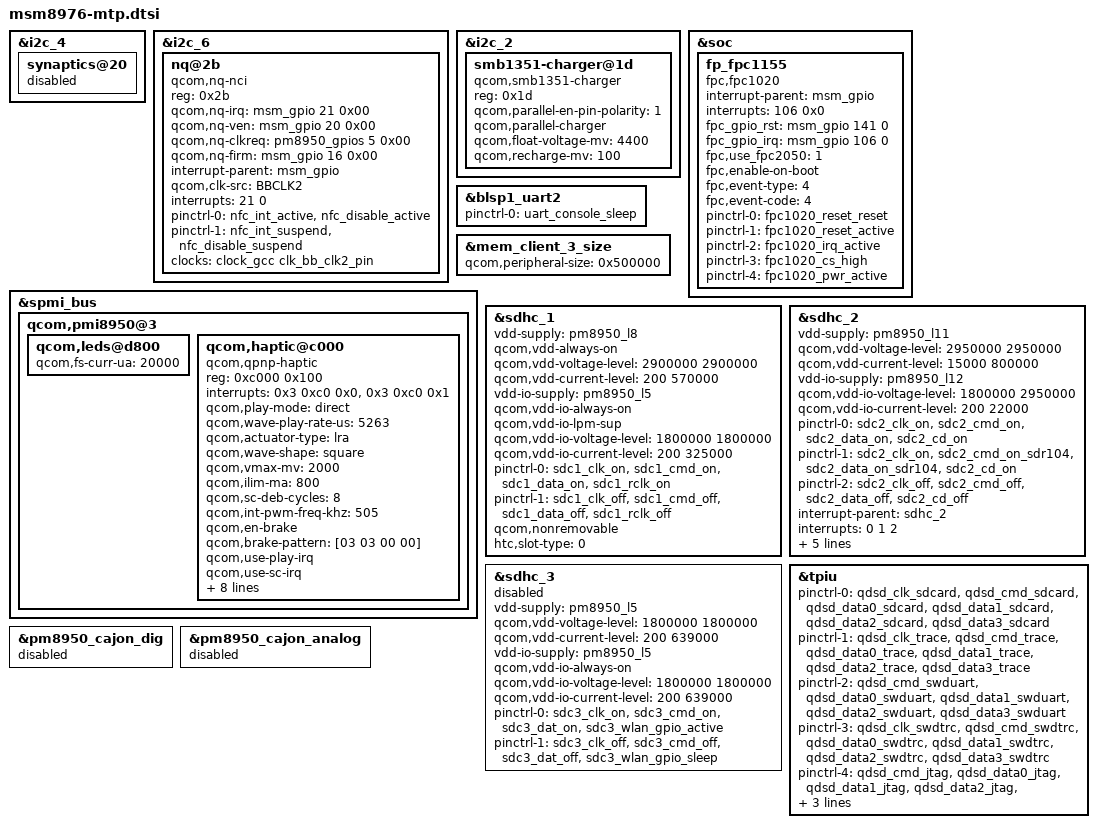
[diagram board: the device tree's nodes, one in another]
/*
 * Copyright (c) 2015, The Linux Foundation. All rights reserved.
 *
 * This program is free software; you can redistribute it and/or modify
 * it under the terms of the GNU General Public License version 2 and
 * only version 2 as published by the Free Software Foundation.
 *
 * This program is distributed in the hope that it will be useful,
 * but WITHOUT ANY WARRANTY; without even the implied warranty of
 * MERCHANTABILITY or FITNESS FOR A PARTICULAR PURPOSE.  See the
 * GNU General Public License for more details.
 */

#include "msm8976-pinctrl.dtsi"
/*#include "msm8976-mdss-mtp.dtsi"*/
#include "msm8976-wsa881x.dtsi"

&i2c_4 { /* BLSP1 QUP4 */
	synaptics@20 {
		status = "disable";
	};
};

&i2c_6 { /* BLSP2 QUP2 */
	nq@2b {
		compatible = "qcom,nq-nci";
		reg = <0x2b>;
		qcom,nq-irq = <&msm_gpio 21 0x00>;
		qcom,nq-ven = <&msm_gpio 20 0x00>;
		qcom,nq-clkreq = <&pm8950_gpios 5 0x00>;
		qcom,nq-firm = <&msm_gpio 16 0x00>;
		interrupt-parent = <&msm_gpio>;
		qcom,clk-src = "BBCLK2";
		interrupts = <21 0>;
		interrupt-names = "nfc_irq";
		pinctrl-names = "nfc_active", "nfc_suspend";
		pinctrl-0 = <&nfc_int_active &nfc_disable_active>;
		pinctrl-1 = <&nfc_int_suspend &nfc_disable_suspend>;
		clocks = <&clock_gcc clk_bb_clk2_pin>;
		clock-names = "ref_clk";
	};
};

&i2c_2 {
	/* Parallel-charger configuration */
	smb1351-charger@1d {
		compatible = "qcom,smb1351-charger";
		reg = <0x1d>;
		qcom,parallel-en-pin-polarity = <1>;
		qcom,parallel-charger;
		qcom,float-voltage-mv = <4400>;
		qcom,recharge-mv = <100>;
	};
};

// Fingerprint +++
&soc{
   fp_fpc1155 {
         compatible = "fpc,fpc1020";
                 interrupt-parent  = <&msm_gpio>;
                 interrupts        = <106 0x0>;
                 fpc_gpio_rst = <&msm_gpio 141 0>;
                 fpc_gpio_irq = <&msm_gpio 106 0>;
                 fpc,use_fpc2050   = <1>;
                 fpc,enable-on-boot;
                 /delete-property/ fpc,enable-wakeup;
                 // EV_MSC, MSC_SCAN
                 fpc,event-type = <4>;
                 fpc,event-code = <4>;
                 pinctrl-names     = "fpc1020_reset_reset",
                                     "fpc1020_reset_active",
                                     "fpc1020_irq_active",
                                     "fpc1020_cs_high",
                                     "fpc1020_pwr_active";
                                     //"fpc1020_spi_active",
                                     //"fpc1020_spi_suspend",
                 pinctrl-0         = <&fpc1020_reset_reset>;
                 pinctrl-1         = <&fpc1020_reset_active>;
                 pinctrl-2         = <&fpc1020_irq_active>;
                 pinctrl-3         = <&fpc1020_cs_high>;
                 pinctrl-4         = <&fpc1020_pwr_active>;
                 //pinctrl-3         = <&fpc1020_spi_active>;
                 //pinctrl-4         = <&fpc1020_spi_suspend>;

    };
};
// Fingerprint ---

//HTC_AUD++
/*
&soc {

	sound-9335 {
		qcom,msm-gpios =
			"quin_i2s",
			"us_eu_gpio";
		qcom,pinctrl-names =
			"all_off",
			"quin_act",
			"us_eu_gpio_act",
			"quin_us_eu_gpio_act";
		pinctrl-names =
			"all_off",
			"quin_act",
			"us_eu_gpio_act",
			"quin_us_eu_gpio_act";
		pinctrl-0 = <&pri_tlmm_lines_sus &cross_conn_det_sus>;
		pinctrl-1 = <&pri_tlmm_lines_act &cross_conn_det_sus>;
		pinctrl-2 = <&pri_tlmm_lines_sus &cross_conn_det_act>;
		pinctrl-3 = <&pri_tlmm_lines_act &cross_conn_det_act>;
		qcom,cdc-us-euro-gpios = <&msm_gpio 144 0>;
	};
};
*/
//HTC_AUD--

&blsp1_uart2 {
	status = "ok";
	pinctrl-names = "default";
	pinctrl-0 = <&uart_console_sleep>;
};

&mem_client_3_size {
	qcom,peripheral-size = <0x500000>;
};

&spmi_bus {
	qcom,pmi8950@3 {
		qcom,leds@d800 {
			qcom,fs-curr-ua = <20000>;
		};

		qcom,haptic@c000 {
			compatible = "qcom,qpnp-haptic";
			reg = <0xc000 0x100>;
			interrupts = <0x3 0xc0 0x0>,
				<0x3 0xc0 0x1>;
			interrupt-names = "sc-irq", "play-irq";
			qcom,play-mode = "direct";
			qcom,wave-play-rate-us = <5263>;
			qcom,actuator-type = "lra";
			qcom,wave-shape = "square";
			qcom,vmax-mv = <2000>;
			qcom,ilim-ma = <800>;
			qcom,sc-deb-cycles = <8>;
			qcom,int-pwm-freq-khz = <505>;
			qcom,en-brake;
			qcom,brake-pattern = [03 03 00 00];
			qcom,use-play-irq;
			qcom,use-sc-irq;
			qcom,wave-samples = [3e 3e 3e 3e 3e 3e 3e 3e];
			qcom,wave-rep-cnt = <1>;
			qcom,wave-samp-rep-cnt = <1>;
			qcom,lra-auto-res-mode="qwd";
			qcom,lra-high-z="opt1";
			qcom,lra-res-cal-period = <0>;
			qcom,correct-lra-drive-freq;
			qcom,misc-trim-error-rc19p2-clk-reg-present;
		};
	};
};

&sdhc_1 {
	vdd-supply = <&pm8950_l8>;
	qcom,vdd-always-on;
	qcom,vdd-voltage-level = <2900000 2900000>;
	qcom,vdd-current-level = <200 570000>;

	vdd-io-supply = <&pm8950_l5>;
	qcom,vdd-io-always-on;
	qcom,vdd-io-lpm-sup;
	qcom,vdd-io-voltage-level = <1800000 1800000>;
	qcom,vdd-io-current-level = <200 325000>;

	pinctrl-names = "active", "sleep";
	pinctrl-0 = <&sdc1_clk_on &sdc1_cmd_on &sdc1_data_on &sdc1_rclk_on>;
	pinctrl-1 = <&sdc1_clk_off &sdc1_cmd_off &sdc1_data_off &sdc1_rclk_off>;

	qcom,nonremovable;

	htc,slot-type = <0>;
	status = "ok";
};

&sdhc_2 {
	vdd-supply = <&pm8950_l11>;
	qcom,vdd-voltage-level = <2950000 2950000>;
	qcom,vdd-current-level = <15000 800000>;

	vdd-io-supply = <&pm8950_l12>;
	qcom,vdd-io-voltage-level = <1800000 2950000>;
	qcom,vdd-io-current-level = <200 22000>;

	pinctrl-names = "active", "active_sdr104", "sleep";
	pinctrl-0 = <&sdc2_clk_on &sdc2_cmd_on &sdc2_data_on &sdc2_cd_on>;
	pinctrl-1 = <&sdc2_clk_on &sdc2_cmd_on_sdr104 &sdc2_data_on_sdr104 &sdc2_cd_on>;
	pinctrl-2 = <&sdc2_clk_off &sdc2_cmd_off &sdc2_data_off &sdc2_cd_off>;

	#address-cells = <0>;
	interrupt-parent = <&sdhc_2>;
	interrupts = <0 1 2>;
	#interrupt-cells = <1>;
	interrupt-map-mask = <0xffffffff>;
	interrupt-map = <0 &intc 0 125 0
			1 &intc 0 221 0
			2 &msm_gpio 100 0>;
	interrupt-names = "hc_irq", "pwr_irq", "status_irq";
	cd-gpios = <&msm_gpio 100 0x1>;

	htc,slot-type = <1>;
	status = "ok";
};

&sdhc_3 {
	vdd-supply = <&pm8950_l5>;
	qcom,vdd-voltage-level = <1800000 1800000>;
	qcom,vdd-current-level = <200 639000>;

	vdd-io-supply = <&pm8950_l5>;
	qcom,vdd-io-always-on;
	qcom,vdd-io-voltage-level = <1800000 1800000>;
	qcom,vdd-io-current-level = <200 639000>;

	pinctrl-names = "active", "sleep";
	pinctrl-0 = <&sdc3_clk_on &sdc3_cmd_on &sdc3_dat_on
					&sdc3_wlan_gpio_active>;
	pinctrl-1 = <&sdc3_clk_off &sdc3_cmd_off &sdc3_dat_off
					&sdc3_wlan_gpio_sleep>;

	status = "disabled";
};

/* htc_battery_porting +++ */
/*
/{
	mtp_batterydata: qcom,battery-data {
		qcom,batt-id-range-pct = <15>;
		#include "batterydata-itech-3000mah-4200mv.dtsi"
		#include "batterydata-itech-3000mah.dtsi"
	};
};

&pmi8950_fg {
	qcom,battery-data = <&mtp_batterydata>;
};

&pmi8950_charger {
	qcom,battery-data = <&mtp_batterydata>;
	qcom,chg-led-support;
	qcom,chg-led-sw-controls;
};
*/
/* htc_battery_porting --- */

/* CoreSight */
&tpiu {
	pinctrl-names = "sdcard", "trace", "swduart",
			"swdtrc", "jtag", "spmi";
	/* NIDnT */
	pinctrl-0 = <&qdsd_clk_sdcard &qdsd_cmd_sdcard
		     &qdsd_data0_sdcard &qdsd_data1_sdcard
		     &qdsd_data2_sdcard &qdsd_data3_sdcard>;
	pinctrl-1 = <&qdsd_clk_trace &qdsd_cmd_trace
		     &qdsd_data0_trace &qdsd_data1_trace
		     &qdsd_data2_trace &qdsd_data3_trace>;
	pinctrl-2 = <&qdsd_cmd_swduart &qdsd_data0_swduart
		     &qdsd_data1_swduart &qdsd_data2_swduart
		     &qdsd_data3_swduart>;
	pinctrl-3 = <&qdsd_clk_swdtrc &qdsd_cmd_swdtrc
		     &qdsd_data0_swdtrc &qdsd_data1_swdtrc
		     &qdsd_data2_swdtrc &qdsd_data3_swdtrc>;
	pinctrl-4 = <&qdsd_cmd_jtag &qdsd_data0_jtag
		     &qdsd_data1_jtag &qdsd_data2_jtag
		     &qdsd_data3_jtag>;
	pinctrl-5 = <&qdsd_clk_spmi &qdsd_cmd_spmi
		     &qdsd_data0_spmi &qdsd_data3_spmi>;
};
//HTC_AUD_START
/*&slim_msm {
	tasha_codec {
		swr_master {
			compatible = "qcom,swr-wcd";
			#address-cells = <2>;
			#size-cells = <0>;
			wsa881x@20170212 {
				compatible = "qcom,wsa881x";
				reg = <0x00 0x20170212>;
				pinctrl-names = "wsa_spkr_sd_act",
						"wsa_spkr_sd_sus";
				pinctrl-0 = <&wsa_spkr_sd_act>;
				pinctrl-1 = <&wsa_spkr_sd_sus>;
			};

			wsa881x@20170211 {
				compatible = "qcom,wsa881x";
				reg = <0x00 0x20170211>;
				pinctrl-names = "wsa_spkr_sd_act",
						"wsa_spkr_sd_sus";
				pinctrl-0 = <&wsa_spkr_sd_act>;
				pinctrl-1 = <&wsa_spkr_sd_sus>;
			};
		};
	};
};
*/
//HTC_AUD_END

&pm8950_cajon_dig {
	status = "disabled";
};

&pm8950_cajon_analog {
	status = "disabled";
};

